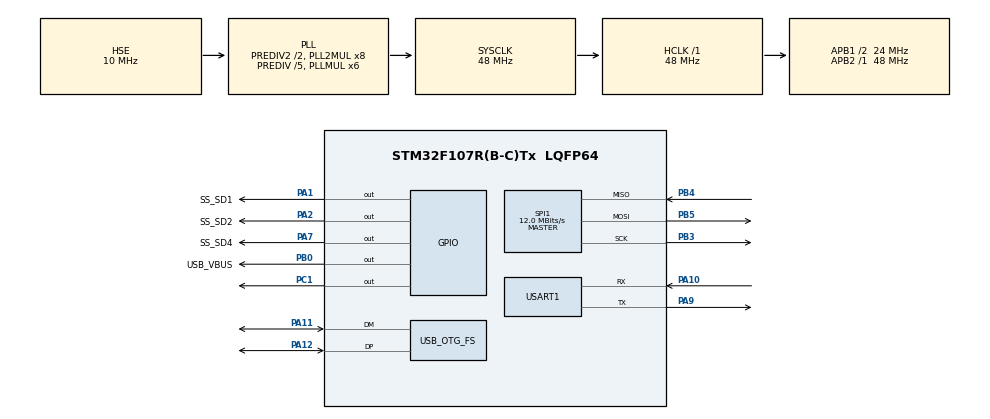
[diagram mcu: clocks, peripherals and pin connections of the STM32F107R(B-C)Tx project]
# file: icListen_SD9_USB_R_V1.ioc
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FREERTOS.Queues01=AppliEvent,16,uint16_t,0,Dynamic,NULL,NULL;USB_rx,80,uint8_t,0,Dynamic,NULL,NULL
FREERTOS.Tasks01=defaultTask,0,256,StartDefaultTask,Default,NULL,Dynamic,NULL,NULL;storage_t,0,256,storage_f,Default,NULL,Dynamic,NULL,NULL
FREERTOS.configLIBRARY_MAX_SYSCALL_INTERRUPT_PRIORITY=5
FREERTOS.configTOTAL_HEAP_SIZE=8000
FREERTOS.configUSE_NEWLIB_REENTRANT=1
Mcu.Family=STM32F1
Mcu.Name=STM32F107R(B-C)Tx
Mcu.Package=LQFP64
NVIC.OTG_FS_IRQn=true\:5\:0\:true\:false\:true\:true\:true\:true\:true
NVIC.PriorityGroup=NVIC_PRIORITYGROUP_4
NVIC.SPI1_IRQn=true\:5\:0\:true\:false\:true\:true\:true\:true\:true
NVIC.TIM1_UP_IRQn=true\:15\:0\:false\:false\:true\:false\:false\:true\:true
NVIC.TIM2_IRQn=true\:5\:0\:true\:false\:true\:true\:true\:true\:true
NVIC.TimeBase=TIM1_UP_IRQn
NVIC.TimeBaseIP=TIM1
NVIC.USART1_IRQn=true\:5\:0\:true\:false\:true\:true\:true\:true\:true
PA1.GPIO_Label=SS_SD1
PA1.PinState=GPIO_PIN_SET
PA1.Signal=GPIO_Output
PA10.Mode=Asynchronous
PA10.Signal=USART1_RX
PA11.Mode=Host_Only
PA11.Signal=USB_OTG_FS_DM
PA12.Mode=Host_Only
PA12.Signal=USB_OTG_FS_DP
PA2.GPIO_Label=SS_SD2
PA2.PinState=GPIO_PIN_SET
PA2.Signal=GPIO_Output
PA7.GPIO_Label=SS_SD4
PA7.PinState=GPIO_PIN_SET
PA7.Signal=GPIO_Output
PA9.Mode=Asynchronous
PA9.Signal=USART1_TX
PB0.GPIO_Label=USB_VBUS
PB0.Signal=GPIO_Output
PB3.Mode=Full_Duplex_Master
PB3.Signal=SPI1_SCK
PB4.Mode=Full_Duplex_Master
PB4.Signal=SPI1_MISO
PB5.Mode=Full_Duplex_Master
PB5.Signal=SPI1_MOSI
PC1.Signal=GPIO_Output
PD0-OSC_IN.Mode=HSE-External-Oscillator
PD0-OSC_IN.Signal=RCC_OSC_IN
PD1-OSC_OUT.Mode=HSE-External-Oscillator
PD1-OSC_OUT.Signal=RCC_OSC_OUT
ProjectManager.HeapSize=0x200
ProjectManager.StackSize=0x400
ProjectManager.TargetToolchain=STM32CubeIDE
RCC.AHBFreq_Value=48000000
RCC.APB1CLKDivider=RCC_HCLK_DIV2
RCC.APB1Freq_Value=24000000
RCC.APB1TimFreq_Value=48000000
RCC.APB2Freq_Value=48000000
RCC.APB2TimFreq_Value=48000000
RCC.HCLKFreq_Value=48000000
RCC.HSEDivPLL=RCC_HSE_PREDIV_DIV5
RCC.HSE_VALUE=10000000
RCC.PLLMUL=RCC_PLL_MUL6
RCC.Prediv1Source=RCC_PREDIV1_SOURCE_PLL2
RCC.Prediv2=RCC_HSE_PREDIV2_DIV2
RCC.SYSCLKFreq_VALUE=48000000
RCC.SYSCLKSource=RCC_SYSCLKSOURCE_PLLCLK
RCC.USBFreq_Value=48000000
RCC.USBPrescaler=RCC_USBCLKSOURCE_PLL_DIV2
SPI1.BaudRatePrescaler=SPI_BAUDRATEPRESCALER_4
SPI1.CalculateBaudRate=12.0 MBits/s
SPI1.Direction=SPI_DIRECTION_2LINES
SPI1.Mode=SPI_MODE_MASTER
SPI1.VirtualType=VM_MASTER
TIM2.Prescaler=39999
USART1.VirtualMode=VM_ASYNC
USB_HOST.BSP.number=1
USB_HOST.USBH_HandleTypeDef=hUsbHostFS
USB_HOST.USBH_MAX_DATA_BUFFER=512
USB_HOST.USBH_MAX_NUM_CONFIGURATION=1
USB_HOST.USBH_MAX_NUM_ENDPOINTS=2
USB_HOST.USBH_MAX_NUM_INTERFACES=2
USB_HOST.USBH_MAX_NUM_SUPPORTED_CLASS=1
USB_HOST.USBH_PROCESS_PRIO=osPriorityHigh
USB_HOST.USBH_PROCESS_STACK_SIZE=256
USB_HOST.USBH_USE_OS-CDC_FS=0
USB_HOST.VirtualModeFS=Cdc
USB_HOST0.BSP.STBoard=false
USB_HOST0.BSP.api=Unknown
USB_HOST0.BSP.i2caddr=0
USB_HOST0.BSP.instance=PB0
USB_HOST0.BSP.ip=GPIO
USB_HOST0.BSP.mode=Output
USB_HOST0.BSP.name=Drive_VBUS_FS
USB_HOST0.BSP.solution=PB0
USB_OTG_FS.Sof_enable=ENABLE
USB_OTG_FS.VirtualMode=Host_Only
VP_FREERTOS_VS_CMSIS_V1.Mode=CMSIS_V1
VP_SYS_VS_ND.Mode=No_Debug
VP_SYS_VS_tim1.Mode=TIM1
VP_TIM2_VS_ClockSourceINT.Mode=Internal
VP_USB_HOST_VS_USB_HOST_CDC_FS.Mode=CDC_FS
board=custom

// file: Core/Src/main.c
/* USER CODE BEGIN Header */
/**
  ******************************************************************************
  * @file           : main.c
  * @brief          : Main program body
  ******************************************************************************
  * @attention
  *
  * <h2><center>&copy; Copyright (c) 2022 STMicroelectronics.
  * All rights reserved.</center></h2>
  *
  * This software component is licensed by ST under Ultimate Liberty license
  * SLA0044, the "License"; You may not use this file except in compliance with
  * the License. You may obtain a copy of the License at:
  *                             www.st.com/SLA0044
  *
  ******************************************************************************
  */
/* USER CODE END Header */
#include "main.h"
#include "cmsis_os.h"
#include "usb_host.h"

/* USER CODE BEGIN Includes */
#include "string.h"
#include "em_sd_storage.h"
#include "wav.h"
#include "icListen.h"

/* USER CODE END Includes */

 SPI_HandleTypeDef hspi1;

TIM_HandleTypeDef htim2;

UART_HandleTypeDef huart1;

osThreadId defaultTaskHandle;
osThreadId storage_tHandle;
osThreadId icListen_tHandle;
osMessageQId AppliEventHandle;
osMessageQId USB_rxHandle;
/* USER CODE BEGIN PV */
extern uint8_t usb_rx_buff[USB_RX_BUFF_SIZE];
extern ApplicationTypeDef Appli_state;
extern USBH_HandleTypeDef hUsbHostFS;
CDC_HandleTypeDef *CDC_Handle;

icListen_wav_full_header* wav_full_hdr_p;

/*
wav_file wav_file1;
wav_file wav_file2;
wav_file wav_file3;
wav_file wav_file4;

sd_storage_t storage1;
*/

char t5[50];

char temp[100];
uint8_t usb_status;
/* USER CODE END PV */

void SystemClock_Config(void);
static void MX_GPIO_Init(void);
static void MX_SPI1_Init(void);
static void MX_USART1_UART_Init(void);
static void MX_TIM2_Init(void);
void StartDefaultTask(void const * argument);
void storage_f(void const * argument);
void icListen_f(void const * argument);

int main(void)
{

  /* MCU Configuration--------------------------------------------------------*/

  /* Reset of all peripherals, Initializes the Flash interface and the Systick. */
  HAL_Init();

  /* Configure the system clock */
  SystemClock_Config();

  /* Initialize all configured peripherals */
  MX_GPIO_Init();
  MX_SPI1_Init();
  MX_USART1_UART_Init();
  MX_TIM2_Init();

  /* Create the queue(s) */
  /* definition and creation of AppliEvent */
  osMessageQDef(AppliEvent, 16, uint16_t);
  AppliEventHandle = osMessageCreate(osMessageQ(AppliEvent), NULL);

  /* definition and creation of USB_rx */
  osMessageQDef(USB_rx, 10, uint32_t);
  USB_rxHandle = osMessageCreate(osMessageQ(USB_rx), NULL);

  /* Create the thread(s) */
  /* definition and creation of defaultTask */
  osThreadDef(defaultTask, StartDefaultTask, osPriorityNormal, 0, 128);
  defaultTaskHandle = osThreadCreate(osThread(defaultTask), NULL);

  /* definition and creation of storage_t */
  osThreadDef(storage_t, storage_f, osPriorityNormal, 0, 512);
  storage_tHandle = osThreadCreate(osThread(storage_t), NULL);

  /* definition and creation of icListen_t */
  osThreadDef(icListen_t, icListen_f, osPriorityNormal, 0, 256);
  icListen_tHandle = osThreadCreate(osThread(icListen_t), NULL);

  /* Start scheduler */
  osKernelStart();

  /* We should never get here as control is now taken by the scheduler */
  /* Infinite loop */
  while (1)
  {

  }
}

void SystemClock_Config(void)
{
  RCC_OscInitTypeDef RCC_OscInitStruct = {0};
  RCC_ClkInitTypeDef RCC_ClkInitStruct = {0};
  RCC_PeriphCLKInitTypeDef PeriphClkInit = {0};

  /** Initializes the RCC Oscillators according to the specified parameters
  * in the RCC_OscInitTypeDef structure.
  */
  RCC_OscInitStruct.OscillatorType = RCC_OSCILLATORTYPE_HSE;
  RCC_OscInitStruct.HSEState = RCC_HSE_ON;
  RCC_OscInitStruct.HSEPredivValue = RCC_HSE_PREDIV_DIV5;
  RCC_OscInitStruct.HSIState = RCC_HSI_ON;
  RCC_OscInitStruct.Prediv1Source = RCC_PREDIV1_SOURCE_PLL2;
  RCC_OscInitStruct.PLL.PLLState = RCC_PLL_ON;
  RCC_OscInitStruct.PLL.PLLSource = RCC_PLLSOURCE_HSE;
  RCC_OscInitStruct.PLL.PLLMUL = RCC_PLL_MUL6;
  RCC_OscInitStruct.PLL2.PLL2State = RCC_PLL2_ON;
  RCC_OscInitStruct.PLL2.PLL2MUL = RCC_PLL2_MUL8;
  RCC_OscInitStruct.PLL2.HSEPrediv2Value = RCC_HSE_PREDIV2_DIV2;
  if (HAL_RCC_OscConfig(&RCC_OscInitStruct) != HAL_OK)
  {
    Error_Handler();
  }

  /** Initializes the CPU, AHB and APB buses clocks
  */
  RCC_ClkInitStruct.ClockType = RCC_CLOCKTYPE_HCLK|RCC_CLOCKTYPE_SYSCLK
                              |RCC_CLOCKTYPE_PCLK1|RCC_CLOCKTYPE_PCLK2;
  RCC_ClkInitStruct.SYSCLKSource = RCC_SYSCLKSOURCE_PLLCLK;
  RCC_ClkInitStruct.AHBCLKDivider = RCC_SYSCLK_DIV1;
  RCC_ClkInitStruct.APB1CLKDivider = RCC_HCLK_DIV2;
  RCC_ClkInitStruct.APB2CLKDivider = RCC_HCLK_DIV1;

  if (HAL_RCC_ClockConfig(&RCC_ClkInitStruct, FLASH_LATENCY_1) != HAL_OK)
  {
    Error_Handler();
  }
  PeriphClkInit.PeriphClockSelection = RCC_PERIPHCLK_USB;
  PeriphClkInit.UsbClockSelection = RCC_USBCLKSOURCE_PLL_DIV2;
  if (HAL_RCCEx_PeriphCLKConfig(&PeriphClkInit) != HAL_OK)
  {
    Error_Handler();
  }

  /** Configure the Systick interrupt time
  */
  __HAL_RCC_PLLI2S_ENABLE();
}

static void MX_SPI1_Init(void)
{

  /* SPI1 parameter configuration*/
  hspi1.Instance = SPI1;
  hspi1.Init.Mode = SPI_MODE_MASTER;
  hspi1.Init.Direction = SPI_DIRECTION_2LINES;
  hspi1.Init.DataSize = SPI_DATASIZE_8BIT;
  hspi1.Init.CLKPolarity = SPI_POLARITY_LOW;
  hspi1.Init.CLKPhase = SPI_PHASE_1EDGE;
  hspi1.Init.NSS = SPI_NSS_SOFT;
  hspi1.Init.BaudRatePrescaler = SPI_BAUDRATEPRESCALER_8;
  hspi1.Init.FirstBit = SPI_FIRSTBIT_MSB;
  hspi1.Init.TIMode = SPI_TIMODE_DISABLE;
  hspi1.Init.CRCCalculation = SPI_CRCCALCULATION_DISABLE;
  hspi1.Init.CRCPolynomial = 10;
  if (HAL_SPI_Init(&hspi1) != HAL_OK)
  {
    Error_Handler();
  }

}

static void MX_TIM2_Init(void)
{

  TIM_ClockConfigTypeDef sClockSourceConfig = {0};
  TIM_MasterConfigTypeDef sMasterConfig = {0};

  htim2.Instance = TIM2;
  htim2.Init.Prescaler = 39999;
  htim2.Init.CounterMode = TIM_COUNTERMODE_UP;
  htim2.Init.Period = 65535;
  htim2.Init.ClockDivision = TIM_CLOCKDIVISION_DIV1;
  htim2.Init.AutoReloadPreload = TIM_AUTORELOAD_PRELOAD_DISABLE;
  if (HAL_TIM_Base_Init(&htim2) != HAL_OK)
  {
    Error_Handler();
  }
  sClockSourceConfig.ClockSource = TIM_CLOCKSOURCE_INTERNAL;
  if (HAL_TIM_ConfigClockSource(&htim2, &sClockSourceConfig) != HAL_OK)
  {
    Error_Handler();
  }
  sMasterConfig.MasterOutputTrigger = TIM_TRGO_RESET;
  sMasterConfig.MasterSlaveMode = TIM_MASTERSLAVEMODE_DISABLE;
  if (HAL_TIMEx_MasterConfigSynchronization(&htim2, &sMasterConfig) != HAL_OK)
  {
    Error_Handler();
  }

}

static void MX_USART1_UART_Init(void)
{

  huart1.Instance = USART1;
  huart1.Init.BaudRate = 115200;
  huart1.Init.WordLength = UART_WORDLENGTH_8B;
  huart1.Init.StopBits = UART_STOPBITS_1;
  huart1.Init.Parity = UART_PARITY_NONE;
  huart1.Init.Mode = UART_MODE_TX_RX;
  huart1.Init.HwFlowCtl = UART_HWCONTROL_NONE;
  huart1.Init.OverSampling = UART_OVERSAMPLING_16;
  if (HAL_UART_Init(&huart1) != HAL_OK)
  {
    Error_Handler();
  }

}

static void MX_GPIO_Init(void)
{
  GPIO_InitTypeDef GPIO_InitStruct = {0};

  /* GPIO Ports Clock Enable */
  __HAL_RCC_GPIOD_CLK_ENABLE();
  __HAL_RCC_GPIOC_CLK_ENABLE();
  __HAL_RCC_GPIOA_CLK_ENABLE();
  __HAL_RCC_GPIOB_CLK_ENABLE();

  /*Configure GPIO pin Output Level */
  HAL_GPIO_WritePin(SS_SD3_GPIO_Port, SS_SD3_Pin, GPIO_PIN_SET);

  /*Configure GPIO pin Output Level */
  HAL_GPIO_WritePin(GPIOA, SS_SD1_Pin|SS_SD2_Pin|SS_SD4_Pin, GPIO_PIN_SET);

  /*Configure GPIO pin Output Level */
  HAL_GPIO_WritePin(USB_VBUS_GPIO_Port, USB_VBUS_Pin, GPIO_PIN_RESET);

  /*Configure GPIO pin : SS_SD3_Pin */
  GPIO_InitStruct.Pin = SS_SD3_Pin;
  GPIO_InitStruct.Mode = GPIO_MODE_OUTPUT_PP;
  GPIO_InitStruct.Pull = GPIO_NOPULL;
  GPIO_InitStruct.Speed = GPIO_SPEED_FREQ_LOW;
  HAL_GPIO_Init(SS_SD3_GPIO_Port, &GPIO_InitStruct);

  /*Configure GPIO pins : SS_SD1_Pin SS_SD2_Pin SS_SD4_Pin */
  GPIO_InitStruct.Pin = SS_SD1_Pin|SS_SD2_Pin|SS_SD4_Pin;
  GPIO_InitStruct.Mode = GPIO_MODE_OUTPUT_PP;
  GPIO_InitStruct.Pull = GPIO_NOPULL;
  GPIO_InitStruct.Speed = GPIO_SPEED_FREQ_LOW;
  HAL_GPIO_Init(GPIOA, &GPIO_InitStruct);

  /*Configure GPIO pin : USB_VBUS_Pin */
  GPIO_InitStruct.Pin = USB_VBUS_Pin;
  GPIO_InitStruct.Mode = GPIO_MODE_OUTPUT_PP;
  GPIO_InitStruct.Pull = GPIO_NOPULL;
  GPIO_InitStruct.Speed = GPIO_SPEED_FREQ_LOW;
  HAL_GPIO_Init(USB_VBUS_GPIO_Port, &GPIO_InitStruct);

}

/* USER CODE BEGIN 4 */

void HAL_UART_RxCpltCallback(UART_HandleTypeDef *huart)
{
	//HAL_UART_Receive_IT(&huart1,uart_tx_msg,1);
}

/* USER CODE END 4 */

void StartDefaultTask(void const * argument)
{
  /* init code for USB_HOST */
  MX_USB_HOST_Init();
  /* USER CODE BEGIN 5 */

   osEvent event;
   HAL_UART_Transmit(&huart1,"USB start\n",10,100);
  /* Infinite loop */
  for(;;)
  {
	  event = osMessageGet(AppliEventHandle, osWaitForever);

	  if(event.status == osEventMessage)
	  {
		switch(event.value.v)
		{
		 case APPLICATION_DISCONNECT:
			 usb_status=0;
		 break;

		 case APPLICATION_READY:
			 osDelay(5000);
			 usb_status=1;
		 break;

		 case APPLICATION_START:
		   //set_line_coding();
		 break;

		 default:
		 break;
		 }
	   }
  }

  /* USER CODE END 5 */
}

void storage_f(void const * argument)
{
  /* USER CODE BEGIN storage_f */
  osDelay(500);

  /*
  HAL_UART_Transmit(&huart1,"FATFS start\n",12,100);

  sd_storage_link_ss(&storage1,0,SS_SD1_Pin,GPIOA);
  sd_storage_link_ss(&storage1,1,SS_SD2_Pin,GPIOA);
  sd_storage_link_ss(&storage1,2,SS_SD3_Pin,SS_SD3_GPIO_Port);
  sd_storage_link_ss(&storage1,3,SS_SD4_Pin,GPIOA);
  sd_storage_init(&storage1);

  for(int i=0;i<SD_STORAGE_NUM_DISKS;i++)
  {
	sprintf(t5,"I:%d S:%d T:%d F:%d\n",i,storage1.disks[i].status,storage1.disks[i].size,storage1.disks[i].free_space);
	HAL_UART_Transmit(&huart1,t5,strlen(t5),100);
  }

  wav_file_open(&wav_file1,"0:test1.wav");
  wav_file_write(&wav_file1,"Test1.wav",8);
  wav_file_close(&wav_file1);

  wav_file_open(&wav_file2,"1:test2.wav");
  wav_file_write(&wav_file2,"Test2.wav",8);
  wav_file_close(&wav_file2);

  wav_file_open(&wav_file3,"2:test3.wav");
  wav_file_write(&wav_file3,"Test3.wav",8);
  wav_file_close(&wav_file3);

  wav_file_open(&wav_file4,"3:test4.wav");
  wav_file_write(&wav_file4,"Test4.wav",8);
  wav_file_close(&wav_file4);

  HAL_UART_Transmit(&huart1,"\nread SD1\n",10,100);
  readDir("0:/");
  HAL_UART_Transmit(&huart1,"read SD2\n",9,100);
  readDir("1:/");
  HAL_UART_Transmit(&huart1,"read SD3\n",9,100);
  readDir("2:/");
  HAL_UART_Transmit(&huart1,"read SD4\n",9,100);
  readDir("3:/");

  f_unlink("0:test1.wav");
  f_unlink("1:test2.wav");
  f_unlink("2:test3.wav");
  f_unlink("3:test4.wav");

  HAL_UART_Transmit(&huart1,"\nread SD1\n",10,100);
  readDir("0:/");
  HAL_UART_Transmit(&huart1,"read SD2\n",9,100);
  readDir("1:/");
  HAL_UART_Transmit(&huart1,"read SD3\n",9,100);
  readDir("2:/");
  HAL_UART_Transmit(&huart1,"read SD4\n",9,100);
  readDir("3:/");

  HAL_UART_Transmit(&huart1,"FATFS finished\n",15,100);
  */

  /* Infinite loop */
  for(;;)
  {
    osDelay(200);
  }
  /* USER CODE END storage_f */
}

void icListen_f(void const * argument)
{
  /* USER CODE BEGIN icListen_f */
	osEvent event;
  /* Infinite loop */
  usb_status=0;
  uint16_t prev_seq;

  while(usb_status==0)
  {
	  osDelay(1);
  }
  set_time();
  osDelay(100);
  enquire_device();
  osDelay(100);
  job_setup();
  osDelay(2000);
  collect_data();
  for(;;)
  {
	  if(usb_status==1){
	   event = osMessageGet(USB_rxHandle, osWaitForever);
	   if(event.status == osEventMessage)
	   {
		   if(event.value.v!=(prev_seq+1) || event.value.v==0){
	         //sprintf(temp,"Type:%d Len:%d\n",wav_full_hdr_p->basic_hdr.type,wav_full_hdr_p->basic_hdr.length);
	         //HAL_UART_Transmit(&huart1,temp,strlen(temp),100);
	         //sprintf(temp,"Mask:%d\n",wav_full_hdr_p->mask_hdr.mask);
	         //HAL_UART_Transmit(&huart1,temp,strlen(temp),100);
	         //sprintf(temp,"S:%d D:%d L:%d G:%d S:%d HS:%d MF:%d\n",wav_full_hdr_p->wav_hdr.seq_num,wav_full_hdr_p->wav_hdr.bit_depth,wav_full_hdr_p->wav_hdr.num_of_bytes,wav_full_hdr_p->wav_hdr.gain,wav_full_hdr_p->wav_hdr.sample_rate,wav_full_hdr_p->wav_hdr.sensitivity,wav_full_hdr_p->wav_hdr.full_scale_mv);
	         //HAL_UART_Transmit(&huart1,temp,strlen(temp),100);
		     sprintf(temp,"Seq:%d\n",event.value.v);
		     HAL_UART_Transmit(&huart1,temp,strlen(temp),100);
		   }
		   prev_seq=event.value.v;
		 }
	   }

  }
  /* USER CODE END icListen_f */
}

void HAL_TIM_PeriodElapsedCallback(TIM_HandleTypeDef *htim)
{
  if (htim->Instance == TIM1) {
    HAL_IncTick();
  }
}

void Error_Handler(void)
{
  __disable_irq();
  while (1)
  {
  }
}

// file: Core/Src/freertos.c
/* USER CODE BEGIN Header */
/**
  ******************************************************************************
  * File Name          : freertos.c
  * Description        : Code for freertos applications
  ******************************************************************************
  * @attention
  *
  * <h2><center>&copy; Copyright (c) 2022 STMicroelectronics.
  * All rights reserved.</center></h2>
  *
  * This software component is licensed by ST under Ultimate Liberty license
  * SLA0044, the "License"; You may not use this file except in compliance with
  * the License. You may obtain a copy of the License at:
  *                             www.st.com/SLA0044
  *
  ******************************************************************************
  */
/* USER CODE END Header */

#include "FreeRTOS.h"
#include "task.h"
#include "main.h"

/* GetIdleTaskMemory prototype (linked to static allocation support) */
void vApplicationGetIdleTaskMemory( StaticTask_t **ppxIdleTaskTCBBuffer, StackType_t **ppxIdleTaskStackBuffer, uint32_t *pulIdleTaskStackSize );

/* USER CODE BEGIN GET_IDLE_TASK_MEMORY */
static StaticTask_t xIdleTaskTCBBuffer;
static StackType_t xIdleStack[configMINIMAL_STACK_SIZE];

void vApplicationGetIdleTaskMemory( StaticTask_t **ppxIdleTaskTCBBuffer, StackType_t **ppxIdleTaskStackBuffer, uint32_t *pulIdleTaskStackSize )
{
  *ppxIdleTaskTCBBuffer = &xIdleTaskTCBBuffer;
  *ppxIdleTaskStackBuffer = &xIdleStack[0];
  *pulIdleTaskStackSize = configMINIMAL_STACK_SIZE;
  /* place for user code */
}
/* USER CODE END GET_IDLE_TASK_MEMORY */
